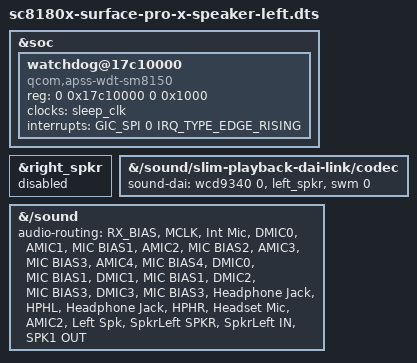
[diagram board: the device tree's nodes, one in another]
// SPDX-License-Identifier: GPL-2.0

/*
 * Conservative speaker test: retain the stock reserved-memory layout and
 * expose one logical WSA881x slave to ASoC. Both physical amplifiers share
 * the bus and receive device number 1, but only one Linux codec component is
 * needed to configure the SoundWire stream and PA path.
 */
#include "sc8180x-surface-pro-x.dts"

/*
 * Keep the hardware watchdog available during the guarded speaker test. This
 * node is byte-for-byte equivalent to the watchdog used by the proven camera
 * test DTBs; the common SC8180X DTS currently omits it.
 */
&soc {
	watchdog@17c10000 {
		compatible = "qcom,apss-wdt-sm8150", "qcom,kpss-wdt";
		reg = <0 0x17c10000 0 0x1000>;
		clocks = <&sleep_clk>;
		interrupts = <GIC_SPI 0 IRQ_TYPE_EDGE_RISING>;
	};
};

&right_spkr {
	status = "disabled";
};

&{/sound/slim-playback-dai-link/codec} {
	sound-dai = <&wcd9340 0>, <&left_spkr>, <&swm 0>;
};

&{/sound} {
	audio-routing =
		"RX_BIAS", "MCLK",
		"Int Mic", "DMIC0",
		"AMIC1", "MIC BIAS1",
		"AMIC2", "MIC BIAS2",
		"AMIC3", "MIC BIAS3",
		"AMIC4", "MIC BIAS4",
		"DMIC0", "MIC BIAS1",
		"DMIC1", "MIC BIAS1",
		"DMIC2", "MIC BIAS3",
		"DMIC3", "MIC BIAS3",
		"Headphone Jack", "HPHL",
		"Headphone Jack", "HPHR",
		"Headset Mic", "AMIC2",
		"Left Spk", "SpkrLeft SPKR",
		"SpkrLeft IN", "SPK1 OUT";
};

/*
 * SPX: the codec-internal SWR master IRQ is needed for the bus to
 * function. On Jun 29 the bus worked with the IRQ present (dtb.wsairq).
 * Without it, MCP_SLV_STATUS stays 0x0 on every boot. The force-attach
 * code now masks interrupts during the critical section (spx_blind_attach
 * + interrupt CPU_EN/mask writes), so the ISR no longer corrupts the
 * CMD FIFO.
 */
